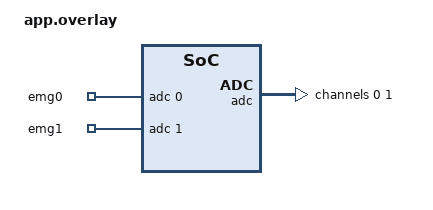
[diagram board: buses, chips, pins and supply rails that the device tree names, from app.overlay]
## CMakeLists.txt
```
cmake_minimum_required(VERSION 3.20.0)

find_package(Zephyr REQUIRED HINTS $ENV{ZEPHYR_BASE})

project(wearable)

target_sources(app PRIVATE
    src/main.c
    src/imu.c
    src/orientation.c
    src/emg.c
    src/emg_model.c
    src/emg_inference.c
    src/gesture_engine.c
    src/sensor_stream.c
    src/ble.c
    src/swipe.c
    ../common/myo_ble_client.c
)

target_include_directories(app PRIVATE
    ${CMAKE_CURRENT_SOURCE_DIR}/../common
)
```

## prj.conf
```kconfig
CONFIG_GPIO=y

# Zephyr logging
CONFIG_LOG=y
CONFIG_LOG_DEFAULT_LEVEL=3
CONFIG_LOG_MODE_DEFERRED=y

# IMU
CONFIG_SENSOR=y
CONFIG_I2C=y
CONFIG_REGULATOR=y
CONFIG_LSM6DSL=y

CONFIG_ADC=y

# BLE Central
CONFIG_BT=y
CONFIG_BT_CENTRAL=y
CONFIG_BT_GATT_CLIENT=y
CONFIG_BT_MAX_CONN=1

# USB CDC serial recording
CONFIG_USB_DEVICE_STACK_NEXT=y
CONFIG_CDC_ACM_SERIAL_INITIALIZE_AT_BOOT=y
CONFIG_SERIAL=y
CONFIG_CONSOLE=y
CONFIG_UART_CONSOLE=y
CONFIG_UART_LINE_CTRL=y
CONFIG_PRINTK=y

# Keep high-rate sample output out of deferred logging.
CONFIG_LOG_PRINTK=n
```

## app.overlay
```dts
#include <zephyr/dt-bindings/adc/nrf-saadc.h>

/ {
    zephyr,user {
        io-channels = <&adc 0>, <&adc 1>;
        io-channel-names = "emg0", "emg1";
    };
};

&adc {
    status = "okay";

    #address-cells = <1>;
    #size-cells = <0>;

    // MyoWare 0 - XIAO D0 (AIN0)
    channel@0 {
        reg = <0>;

        zephyr,gain = "ADC_GAIN_1_6";
        zephyr,reference = "ADC_REF_INTERNAL";
        zephyr,acquisition-time = <ADC_ACQ_TIME_DEFAULT>;

        zephyr,input-positive = <NRF_SAADC_AIN0>;

        zephyr,resolution = <12>;
    };

    // MyoWare 1 - XIAO D1 (AIN1)
    channel@1 {
        reg = <1>;

        zephyr,gain = "ADC_GAIN_1_6";
        zephyr,reference = "ADC_REF_INTERNAL";
        zephyr,acquisition-time = <ADC_ACQ_TIME_DEFAULT>;

        zephyr,input-positive = <NRF_SAADC_AIN1>;

        zephyr,resolution = <12>;
    };
};
```

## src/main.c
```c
#include <errno.h>
#include <math.h>
#include <zephyr/kernel.h>
#include <zephyr/device.h>
#include <zephyr/drivers/gpio.h>
#include <zephyr/logging/log.h>
#include "emg.h"
#include "imu.h"
#include "orientation.h"
#include "ble.h"
#include "myo_ble.h"
#include "sensor_stream.h"
#include "emg_inference.h"
#include "gesture_engine.h"
#include "myo_ble_client.h"

LOG_MODULE_REGISTER(wearable, LOG_LEVEL_INF);

#define LED0_NODE DT_ALIAS(led0)
#define CALIBRATION_SAMPLES 100
#define CALIBRATION_INTERVAL_MS 20
#define CALIBRATION_MAX_DRIFT_COS 0.9781476f
#define SENSOR_WARNING_INTERVAL_MS 1000
#define SAMPLE_INTERVAL_MS 50
#define BLE_HEARTBEAT_MS 500
#define GC_TX_DEPTH 8U
#define GC_TX_MAX_AGE_MS 450U

static const struct gpio_dt_spec led =
    GPIO_DT_SPEC_GET(LED0_NODE, gpios);

// Orientation gate owned by acquisition thread.
static struct gesture_engine gesture_control;

// Short-lived main-thread FIFO: no events survive receiver changes.
struct pending_gesture {
    enum myo_gesture gesture;
    uint32_t created_ms;
    uint32_t link_generation;
};

static struct pending_gesture tx_queue[GC_TX_DEPTH];
static uint8_t tx_head, tx_tail, tx_count;
static uint32_t tx_submitted, tx_dropped;

static void gesture_tx_clear(void)
{
    tx_head = tx_tail = tx_count = 0;
}

static void gesture_tx_pop(void)
{
    if (tx_count == 0U) return;
    tx_head = (uint8_t)((tx_head + 1U) % GC_TX_DEPTH);
    tx_count--;
}

static void gesture_tx_enqueue(enum myo_gesture gesture,
                               uint32_t now_ms)
{
    if (!myo_ble_client_gesture_ready()) {
        tx_dropped++;
        LOG_WRN("Gesture %d dropped: receiver unavailable", (int)gesture);
        return;
    }
    if (tx_count >= GC_TX_DEPTH) {
        tx_dropped++;
        LOG_WRN("Gesture %d dropped: TX queue full", (int)gesture);
        return;
    }

    struct pending_gesture *item = &tx_queue[tx_tail];
    item->gesture = gesture;
    item->created_ms = now_ms;
    item->link_generation = myo_ble_client_link_generation();
    tx_tail = (uint8_t)((tx_tail + 1U) % GC_TX_DEPTH);
    tx_count++;
}

static void gesture_tx_poll(uint32_t now_ms)
{
    while (tx_count > 0U) {
        struct pending_gesture *item = &tx_queue[tx_head];
        if ((uint32_t)(now_ms - item->created_ms) >
                GC_TX_MAX_AGE_MS ||
            item->link_generation != myo_ble_client_link_generation() ||
            !myo_ble_client_gesture_ready()) {
            tx_dropped++;
            gesture_tx_pop();
            continue;
        }

        int err = myo_ble_client_send_gesture(item->gesture);
        if (err == -EAGAIN || err == -ENOMEM) break;

        if (err == 0) {
            tx_submitted++;
            LOG_INF("Gesture BLE submitted: %d", (int)item->gesture);
        } else {
            tx_dropped++;
            LOG_WRN("Gesture BLE submission failed: %d", err);
        }
        gesture_tx_pop();
    }
}


#define EMG_BASELINE_SAMPLES 40
#define EMG_BASELINE_INTERVAL_MS 50
#define EMG_BASELINE_TIMEOUT_MS 5000

static void blink_work_handler(struct k_work *work);

K_WORK_DELAYABLE_DEFINE(blink_work, blink_work_handler);

static void blink_work_handler(struct k_work *work)
{
    ARG_UNUSED(work);

    uint32_t phase = k_uptime_get_32() % 1200U;
    bool ready = myo_ble_client_gesture_ready();

    bool on;
    if (!ready) {
        on = phase < 120U; // Single pulse: disconnected
    } else if (myo_ble_client_get_mode() == MYO_MODE_LIGHT) {
        on = true;         // Solid: Wio ready
    } else {
        on = phase < 120U ||
             (phase >= 280U && phase < 400U); // Laptop ready
    }

    gpio_pin_set_dt(&led, on ? 1 : 0);
    k_work_reschedule(&blink_work, K_MSEC(100));
}


static int capture_emg_baseline(int32_t baseline_mv[2])
{
    if (baseline_mv == NULL) return -EINVAL;

    int64_t sum[2] = {0, 0};
    uint32_t count = 0;
    uint32_t last_sequence = UINT32_MAX;
    int64_t deadline = k_uptime_get() + EMG_BASELINE_TIMEOUT_MS;

    while (count < EMG_BASELINE_SAMPLES &&
           k_uptime_get() < deadline) {
        struct sensor_frame frame;

        if (sensor_stream_latest(&frame) == 0 &&
            frame.sequence != last_sequence) {
            last_sequence = frame.sequence;
            int32_t emg0 = frame.emg.mv[0];
            int32_t emg1 = frame.emg.mv[1];

            if (emg0 < 0 || emg0 > 3300 ||
                emg1 < 0 || emg1 > 3300) {
                return -EINVAL;
            }
            sum[0] += emg0;
            sum[1] += emg1;
            count++;
        }

        k_msleep(EMG_BASELINE_INTERVAL_MS);
    }

    if (count != EMG_BASELINE_SAMPLES) return -EAGAIN;

    baseline_mv[0] = (int32_t)(sum[0] / EMG_BASELINE_SAMPLES);
    baseline_mv[1] = (int32_t)(sum[1] / EMG_BASELINE_SAMPLES);
    return 0;
}

static int capture_startup_reference(
    struct imu_accel_sample *reference)
{
    if (reference == NULL) return -EINVAL;

    int64_t sum_x = 0, sum_y = 0, sum_z = 0;
    struct imu_accel_sample first = {0};
    float first_magnitude = 0.0f;

    for (int i = 0; i < CALIBRATION_SAMPLES; i++) {
        struct imu_accel_sample sample;
        int err = imu_read_accel(&sample);
        if (err < 0) return err;

        float x = (float)sample.x_mg;
        float y = (float)sample.y_mg;
        float z = (float)sample.z_mg;
        float magnitude = sqrtf(x*x + y*y + z*z);

        if (magnitude < 800.0f || magnitude > 1200.0f) {
            return -EAGAIN;
        }

        if (i == 0) {
            first = sample;
            first_magnitude = magnitude;
        } else {
            float dot =
                x * first.x_mg +
                y * first.y_mg +
                z * first.z_mg;

            // Reject calibration if the arm drifts by over 12 degrees.
            if (dot < CALIBRATION_MAX_DRIFT_COS *
                      magnitude * first_magnitude) {
                return -EAGAIN;
            }
        }

        sum_x += sample.x_mg;
        sum_y += sample.y_mg;
        sum_z += sample.z_mg;
        k_msleep(CALIBRATION_INTERVAL_MS);
    }

    reference->x_mg = (int32_t)(sum_x / CALIBRATION_SAMPLES);
    reference->y_mg = (int32_t)(sum_y / CALIBRATION_SAMPLES);
    reference->z_mg = (int32_t)(sum_z / CALIBRATION_SAMPLES);
    return 0;
}

int main(void)
{
    if (!gpio_is_ready_dt(&led)) {
        return 0;
    }

    gpio_pin_configure_dt(&led, GPIO_OUTPUT_INACTIVE);

    LOG_INF("Hand Controlled Smart Light starting");

    k_work_schedule(&blink_work, K_NO_WAIT);

    k_msleep(3000);

    int imu_status = imu_init();

    LOG_INF("imu_init() returned %d", imu_status);

    if (imu_status < 0) {
        LOG_ERR("IMU initialization failed");
        return 0;
    }

    if (emg_init() < 0) {
        LOG_ERR("EMG ADC initialization failed");
        return 0;
    }

    // Capture one shared orientation reference at startup.
    struct imu_accel_sample reference = {0};

    while (1) {
        LOG_INF("STARTUP ORIENTATION CALIBRATION");
        LOG_INF("Hold wearable in your control position.");
        LOG_INF("Hold still during the 2-second capture.");
        LOG_INF("Starting calibration in 2 seconds...");
        k_msleep(2000);

        int err = capture_startup_reference(&reference);
        if (err == 0) {
            LOG_INF("Orientation calibration successful.");
            break;
        }
        LOG_WRN("Calibration failed (%d); retrying...", err);
        k_msleep(500);
    }

    LOG_INF("Gate reference: X=%d Y=%d Z=%d",
            reference.x_mg, reference.y_mg, reference.z_mg);
    LOG_INF("Reference applies to both Light and Laptop modes.");

    // Start BLE after sensor calibration
    if (ble_init() < 0) {
        LOG_ERR("BLE initialization failed");
        return 0;
    }
    // Start continuous EMG + IMU acquisition.
    int stream_err = sensor_stream_start(&reference);
    if (stream_err < 0) {
        LOG_ERR("Sensor stream failed: %d", stream_err);
        return 0;
    }
        
    // Rest-only calibration supports four discrete EMG classes.
    int32_t rest_mv[2] = {0, 0};
    bool emg_calibrated = false;

    for (int attempt = 1; attempt <= 3; attempt++) {
        LOG_INF("EMG REST CALIBRATION");
        LOG_INF("Relax your forearm completely.");
        LOG_INF("Starting in 2 seconds.");
        k_msleep(2000);

        int err = capture_emg_baseline(rest_mv);
        if (err == 0) {
            emg_calibrated = emg_inference_set_baseline(
                rest_mv[0], rest_mv[1]);
            if (emg_calibrated) {
                LOG_INF("EMG calibrated: EMG0=%d mV, EMG1=%d mV",
                        rest_mv[0], rest_mv[1]);
                break;
            }
            err = -EINVAL;
        }
        LOG_WRN("EMG calibration attempt %d failed: %d", attempt, err);
    }

    if (!emg_calibrated) {
        LOG_ERR("EMG calibration failed; reboot to retry.");
        LOG_ERR("IMU acquisition and BLE remain active.");
    }

    sensor_stream_clear_swipes();

    // Start command recognition in the disarmed state.
    gesture_engine_init(&gesture_control);

    uint32_t last_gesture_sequence = UINT32_MAX;


    uint8_t last_sent = 0xff;
    int64_t last_tx_ms = 0;
    int64_t last_log_ms = 0;
    int64_t last_sensor_warning_ms = 0;
    int last_reported_class = -2;
    uint32_t last_swipe_diag_ms = k_uptime_get_32();

    while (1) {
        struct sensor_frame frame = {0};

        int ret = sensor_stream_latest(&frame);        

        bool valid = false;

        if (ret == 0) {

            valid = frame.orientation_valid;

            // Read the latest EMG ML prediction.
            emg_class_t predicted_class = EMG_REST;

            bool prediction_ready =
                emg_inference_latest(&predicted_class);

            int angle = frame.orientation_angle_deg;

            // Run command recognition only for fresh sensor data.
            uint32_t gesture_now = k_uptime_get_32();

            bool fresh_gesture_frame =
                frame.sequence != last_gesture_sequence &&
                (uint32_t)(gesture_now - frame.timestamp_ms) <= 150U;

            if (fresh_gesture_frame) {

                last_gesture_sequence = frame.sequence;

                // Read all pending IMU swipe events.
                // Ignore events older than 350 ms.
                struct swipe_notification notification;
                enum swipe_event pending_swipe = SWIPE_NONE;

                while (sensor_stream_pop_swipe(&notification)) {
                    if ((uint32_t)(
                            gesture_now - notification.timestamp_ms
                        ) <= 350U) {

                        pending_swipe = notification.event;
                    }
                }

                // Suppress FLEX candidates during substantial
                // wrist movement. Raw gyro units are mdps.
                // 35000 mdps = 35 degrees/second.
                const int32_t motion_threshold = 35000;

                bool significant_motion =
                    frame.motion.gyro.x_mdps > motion_threshold ||
                    frame.motion.gyro.x_mdps < -motion_threshold ||
                    frame.motion.gyro.y_mdps > motion_threshold ||
                    frame.motion.gyro.y_mdps < -motion_threshold ||
                    frame.motion.gyro.z_mdps > motion_threshold ||
                    frame.motion.gyro.z_mdps < -motion_threshold;

                // Interpret all seven discrete gestures. Swipes are active
                // in either receiver mode; the sensor thread gated onset.
                enum myo_gesture action = gesture_engine_update(
                    &gesture_control,
                    gesture_now,
                    valid,
                    prediction_ready,
                    prediction_ready ? predicted_class : EMG_UNKNOWN,
                    significant_motion,
                    pending_swipe
                );

                if (pending_swipe != SWIPE_NONE &&
                    action == MYO_GESTURE_NONE) {
                    LOG_INF("Swipe %d suppressed by gesture engine",
                            (int)pending_swipe);
                }

                // A five-second TENSE changes receivers in any pose.
                // A shorter released TENSE remains a normal event.
                if (gesture_engine_take_mode_switch(
                        &gesture_control)) {
                    LOG_INF("Long TENSE: changing receiver mode");
                    sensor_stream_clear_swipes();

                    gesture_tx_clear();
                    int mode_err = myo_ble_client_toggle_mode();
                    if (mode_err) {
                        LOG_WRN("Mode switch error: %d", mode_err);
                    } else {
                        LOG_INF("Receiver mode: %s",
                            myo_ble_client_get_mode() == MYO_MODE_LIGHT
                                ? "LIGHT" : "LAPTOP");
                    }
                }

                if (action != MYO_GESTURE_NONE) {
                    gesture_tx_enqueue(action, gesture_now);
                }
            }

            const char *gesture = "WARMUP";
            int class_code = -1;

            if (prediction_ready) {
                class_code = (int)predicted_class;

                switch (predicted_class) {
                case EMG_REST:
                    gesture = "REST";
                    break;

                case EMG_FLEX:
                    gesture = "FLEX";
                    break;

                case EMG_EXTEND:
                    gesture = "EXTEND";
                    break;

                case EMG_TENSE:
                    gesture = "TENSE";
                    break;

                default:
                    gesture = "UNKNOWN";
                    break;
                }
            }

            int64_t log_now = k_uptime_get();

            // Log periodically and when the classification changes.
            // Throttle changes to avoid flooding the console.
            if ((log_now - last_log_ms >= 250) ||
                (class_code != last_reported_class &&
                log_now - last_log_ms >= 100)) {

                LOG_INF(
                    "EMG0=%d mV | EMG1=%d mV | Gesture=%s | "
                    "Orientation=%s | Angle=%d",
                    frame.emg.mv[0], frame.emg.mv[1], gesture,
                    valid ? "VALID" : "INVALID", angle
                );

                last_reported_class = class_code;
                last_log_ms = log_now;
            }
        } else {
            // Never complete a hold based on missing/stale samples.
            gesture_engine_abort(&gesture_control);
            gesture_tx_clear();
            sensor_stream_clear_swipes();

            int64_t warning_now = k_uptime_get();
            if (warning_now - last_sensor_warning_ms >=
                SENSOR_WARNING_INTERVAL_MS) {
                LOG_WRN("Sensor frame unavailable or stale: %d", ret);
                last_sensor_warning_ms = warning_now;
            }

        }
        
        // Validity heartbeat now means fresh sensor data. The
        // orientation gate remains available for diagnostics only.
        uint8_t state = ret == 0 ? MYO_VALID : MYO_INVALID;

        int64_t now = k_uptime_get();

        if (state != last_sent ||
            now - last_tx_ms >= BLE_HEARTBEAT_MS) {

            if (ble_send_state(state) == 0) {
                last_sent = state;
                last_tx_ms = now;
            }
        }
                
        // Report pipeline failures without printing every IMU sample.
        uint32_t diag_now = k_uptime_get_32();
        if ((uint32_t)(diag_now - last_swipe_diag_ms) >= 3000U) {
            struct swipe_stats stats = {0};
            uint32_t queue_drops = 0;
            sensor_stream_get_swipe_stats(&stats, &queue_drops);

            LOG_INF("SWIPE attempts=%u accepted=%u grace=%u "
                    "gate_blocked=%u below_threshold=%u",
                    stats.attempts, stats.accepted, stats.grace_starts,
                    stats.gate_blocked, stats.below_threshold);

            LOG_INF("SWIPE weak=%u direction=%u ambiguous=%u "
                    "rearms=%u gaps=%u queue_drops=%u",
                    stats.weak_capture, stats.direction_rejected,
                    stats.ambiguous_rejected, stats.rearms, stats.gaps,
                    queue_drops);

            uint32_t acked = 0, rejected = 0;
            myo_ble_client_get_gesture_stats(&acked, &rejected);
            LOG_INF("BLE submitted=%u acked=%u rejected=%u "
                    "dropped=%u pending=%u",
                    tx_submitted, acked, rejected, tx_dropped,
                    (unsigned int)tx_count);

            last_swipe_diag_ms = diag_now;
        }

        // Discrete actions only, never continuous EMG brightness.
        gesture_tx_poll(k_uptime_get_32());
        k_msleep(SAMPLE_INTERVAL_MS);
    }

    return 0;
}
```

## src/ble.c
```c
#include "ble.h"
#include "myo_ble_client.h"

int ble_init(void)
{
    return myo_ble_client_init();
}

int ble_send_state(uint8_t state)
{
    return myo_ble_client_send_state(state);
}
```

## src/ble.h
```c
#ifndef BLE_H
#define BLE_H

#include <stdint.h>

int ble_init(void);
int ble_send_state(uint8_t state);

#endif
```

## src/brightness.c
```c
#include "brightness.h"

#define FILTER_MS 500.0f
#define CONFIRM_MS 250U
#define HYSTERESIS 0.075f

static float clamp(float value, float lo, float hi)
{
    if (value < lo) return lo;
    if (value > hi) return hi;
    return value;
}

void brightness_init(struct brightness_estimator *b,
                     float baseline_mv,
                     float maximum_mv)
{
    if (!b) return;

    if (maximum_mv <= baseline_mv + 1.0f) {
        maximum_mv = baseline_mv + 1.0f;
    }

    *b = (struct brightness_estimator){0};

    b->baseline_mv = baseline_mv;
    b->maximum_mv = maximum_mv;
        
    // Start at a usable 50% brightness.
    b->filtered_mv =
        baseline_mv + 0.5f * (maximum_mv - baseline_mv);

    b->level = 2;
    b->candidate = 2;
    b->initialized = true;
}

uint8_t brightness_get(const struct brightness_estimator *b)
{
    return b ? b->level * 25U : 0U;
}

uint8_t brightness_update(struct brightness_estimator *b,
                          int32_t emg0_mv,
                          uint32_t timestamp_ms,
                          bool orientation_valid)
{
    if (!b || !b->initialized) return 0;

    // Invalid orientation freezes brightness.
    if (!orientation_valid) {
        b->last_ms = timestamp_ms;
        b->candidate_since_ms = 0;
        b->candidate = b->level;
        return brightness_get(b);
    }

    uint32_t dt = timestamp_ms - b->last_ms;

    if (b->last_ms == 0 || dt > 1000U) {
        dt = 10U;
    }

    b->last_ms = timestamp_ms;

    // Time-based low-pass filter, compatible with
    // either 20 Hz testing or 100 Hz integration.
    float alpha = (float)dt / (FILTER_MS + (float)dt);

    b->filtered_mv += alpha *
        ((float)emg0_mv - b->filtered_mv);

    float intensity =
        (b->filtered_mv - b->baseline_mv) /
        (b->maximum_mv - b->baseline_mv);

    intensity = clamp(intensity, 0.0f, 1.0f);

    uint8_t proposed = b->level;

    // Adjacent-level thresholds with hysteresis.
    // Moving only one step at a time reduces jumps.
    if (b->level < 4) {
        float up_threshold =
            ((float)b->level + 0.5f) / 4.0f;

        if (intensity > up_threshold + HYSTERESIS) {
            proposed = b->level + 1;
        }
    }

    if (b->level > 0) {
        float down_threshold =
            ((float)b->level - 0.5f) / 4.0f;

        if (intensity < down_threshold - HYSTERESIS) {
            proposed = b->level - 1;
        }
    }

    if (proposed == b->level) {
        b->candidate = b->level;
        b->candidate_since_ms = 0;
        return brightness_get(b);
    }

    if (proposed != b->candidate ||
        b->candidate_since_ms == 0) {
        b->candidate = proposed;
        b->candidate_since_ms = timestamp_ms;
        return brightness_get(b);
    }

    if ((uint32_t)(timestamp_ms - b->candidate_since_ms)
        >= CONFIRM_MS) {
        b->level = proposed;
        b->candidate_since_ms = 0;
    }

    return brightness_get(b);
}
```

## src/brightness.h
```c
#ifndef BRIGHTNESS_H
#define BRIGHTNESS_H

#include <stdbool.h>
#include <stdint.h>

struct brightness_estimator {
    float baseline_mv;
    float maximum_mv;
    float filtered_mv;
    uint32_t last_ms;
    uint32_t candidate_since_ms;
    uint8_t level;
    uint8_t candidate;
    bool initialized;
};

void brightness_init(struct brightness_estimator *b,
                     float baseline_mv,
                     float maximum_mv);

uint8_t brightness_update(struct brightness_estimator *b,
                          int32_t emg0_mv,
                          uint32_t timestamp_ms,
                          bool orientation_valid);

uint8_t brightness_get(const struct brightness_estimator *b);

#endif
```

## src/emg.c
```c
#include "emg.h"

#include <errno.h>

#include <zephyr/device.h>
#include <zephyr/devicetree.h>
#include <zephyr/drivers/adc.h>
#include <zephyr/logging/log.h>
#include <zephyr/sys/util.h>

LOG_MODULE_REGISTER(emg, LOG_LEVEL_INF);

#define EMG_NODE DT_PATH(zephyr_user)

static const struct adc_dt_spec emg_adc[EMG_CHANNEL_COUNT] = {
    ADC_DT_SPEC_GET_BY_NAME(EMG_NODE, emg0),
    ADC_DT_SPEC_GET_BY_NAME(EMG_NODE, emg1),
};

int emg_init(void)
{
    // Both channels must use the same ADC peripheral.
    if (emg_adc[0].dev != emg_adc[1].dev) {
        LOG_ERR("EMG channels use different ADC devices");
        return -EINVAL;
    }

    for (int i = 0; i < EMG_CHANNEL_COUNT; i++) {

        if (!adc_is_ready_dt(&emg_adc[i])) {
            LOG_ERR("EMG%d ADC device not ready", i);
            return -ENODEV;
        }

        int ret = adc_channel_setup_dt(&emg_adc[i]);

        if (ret < 0) {
            LOG_ERR("EMG%d ADC setup failed: %d", i, ret);
            return ret;
        }
    }

    LOG_INF("Both EMG ADC channels initialized");

    return 0;
}

int emg_read(struct emg_sample *sample)
{
    if (sample == NULL) {
        return -EINVAL;
    }

    int16_t raw[EMG_CHANNEL_COUNT] = {0};

    // Read both ADC channels in one sampling sequence.
    struct adc_sequence sequence = {
        .channels = BIT(emg_adc[0].channel_id) |
                    BIT(emg_adc[1].channel_id),
        .buffer = raw,
        .buffer_size = sizeof(raw),
        .resolution = emg_adc[0].resolution,
    };

    int ret = adc_read(emg_adc[0].dev, &sequence);

    if (ret < 0) {
        return ret;
    }

    // Convert both ADC readings to millivolts.
    for (int i = 0; i < EMG_CHANNEL_COUNT; i++) {

        sample->raw[i] = raw[i];

        int32_t mv = raw[i];

        ret = adc_raw_to_millivolts_dt(
            &emg_adc[i],
            &mv);

        if (ret < 0) {
            return ret;
        }

        sample->mv[i] = mv;
    }

    return 0;
}
```

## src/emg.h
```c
#ifndef EMG_H
#define EMG_H

#include <stdint.h>

#define EMG_CHANNEL_COUNT 2

struct emg_sample {
    int16_t raw[EMG_CHANNEL_COUNT];
    int32_t mv[EMG_CHANNEL_COUNT];
};

int emg_init(void);
int emg_read(struct emg_sample *sample);

#endif
```

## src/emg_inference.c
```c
#include "emg_inference.h"

#include <stdbool.h>
#include <stdint.h>
#include <zephyr/kernel.h>
#include <zephyr/sys/atomic.h>

#define EMG_CHANNELS 2U
#define EMG_WINDOW 40U
#define EMG_HOP 10U
#define EMG_MAX_GAP_MS 25U
#define CONFIRM_WINDOWS 2U
#define UNKNOWN_TIMEOUT_WINDOWS 3U

#if EMG_FEATURE_COUNT != 8
#error "Dual-channel inference requires eight EMG features"
#endif

K_MUTEX_DEFINE(emg_inference_lock);

static int32_t samples[EMG_CHANNELS][EMG_WINDOW];
static float baseline_mv[EMG_CHANNELS];
static bool baseline_ready;

static uint32_t write_index;
static uint32_t samples_seen;
static uint32_t previous_sequence;
static uint32_t previous_timestamp;
static bool have_previous;

static emg_class_t stable_class = EMG_UNKNOWN;
static emg_class_t candidate_class = EMG_UNKNOWN;
static uint32_t candidate_windows;
static uint32_t unknown_windows;

// Atomically read by the main thread. 0=unavailable; 1..4=class+1.
static atomic_t latest_state;

static void reset_prediction_locked(void)
{
    write_index = 0;
    samples_seen = 0;
    have_previous = false;
    stable_class = EMG_UNKNOWN;
    candidate_class = EMG_UNKNOWN;
    candidate_windows = 0;
    unknown_windows = 0;
    atomic_set(&latest_state, 0);
}

bool emg_inference_set_baseline(int32_t emg0_mv, int32_t emg1_mv)
{
    if (emg0_mv < 0 || emg0_mv > 3300 ||
        emg1_mv < 0 || emg1_mv > 3300) {
        return false;
    }

    k_mutex_lock(&emg_inference_lock, K_FOREVER);
    baseline_mv[0] = (float)emg0_mv;
    baseline_mv[1] = (float)emg1_mv;
    reset_prediction_locked();
    baseline_ready = true;
    k_mutex_unlock(&emg_inference_lock);
    return true;
}

void emg_inference_invalidate(void)
{
    k_mutex_lock(&emg_inference_lock, K_FOREVER);
    reset_prediction_locked();
    k_mutex_unlock(&emg_inference_lock);
}

static void update_stable_class(emg_class_t predicted)
{
    if (predicted == EMG_UNKNOWN) {
        unknown_windows++;
        candidate_class = EMG_UNKNOWN;
        candidate_windows = 0;

        if (unknown_windows >= UNKNOWN_TIMEOUT_WINDOWS) {
            stable_class = EMG_UNKNOWN;
            atomic_set(&latest_state, 0);
        }
        return;
    }

    unknown_windows = 0;

    if (predicted == stable_class) {
        candidate_class = EMG_UNKNOWN;
        candidate_windows = 0;
        return;
    }

    if (predicted != candidate_class) {
        candidate_class = predicted;
        candidate_windows = 1;
        return;
    }

    candidate_windows++;
    if (candidate_windows >= CONFIRM_WINDOWS) {
        stable_class = predicted;
        candidate_class = EMG_UNKNOWN;
        candidate_windows = 0;
        atomic_set(&latest_state, (atomic_val_t)stable_class + 1);
    }
}

void emg_inference_push(
    int32_t emg0_mv,
    int32_t emg1_mv,
    uint32_t sequence,
    uint32_t timestamp_ms)
{
    k_mutex_lock(&emg_inference_lock, K_FOREVER);

    if (!baseline_ready) {
        k_mutex_unlock(&emg_inference_lock);
        return;
    }

    if (emg0_mv < 0 || emg0_mv > 3300 ||
        emg1_mv < 0 || emg1_mv > 3300) {
        reset_prediction_locked();
        k_mutex_unlock(&emg_inference_lock);
        return;
    }

    if (have_previous) {
        uint32_t dt = timestamp_ms - previous_timestamp;
        if (sequence != previous_sequence + 1U ||
            dt == 0U || dt > EMG_MAX_GAP_MS) {
            reset_prediction_locked();
        }
    }

    previous_sequence = sequence;
    previous_timestamp = timestamp_ms;
    have_previous = true;
    samples[0][write_index] = emg0_mv;
    samples[1][write_index] = emg1_mv;
    write_index = (write_index + 1U) % EMG_WINDOW;
    samples_seen++;

    // First complete window takes 400 ms. Predict each 100 ms.
    if (samples_seen < EMG_WINDOW ||
        (samples_seen - EMG_WINDOW) % EMG_HOP != 0U) {
        k_mutex_unlock(&emg_inference_lock);
        return;
    }

    float features[EMG_FEATURE_COUNT];

    for (uint32_t channel = 0; channel < EMG_CHANNELS; channel++) {
        int32_t minimum = samples[channel][0];
        int32_t maximum = samples[channel][0];
        int64_t sum = 0;

        for (uint32_t i = 0; i < EMG_WINDOW; i++) {
            int32_t value = samples[channel][i];
            sum += value;
            if (value < minimum) minimum = value;
            if (value > maximum) maximum = value;
        }

        float mean = (float)sum / (float)EMG_WINDOW;
        float variance_sum = 0.0f;

        for (uint32_t i = 0; i < EMG_WINDOW; i++) {
            float difference = (float)samples[channel][i] - mean;
            variance_sum += difference * difference;
        }

        uint32_t idx = channel * 4U;
        features[idx] = mean;
        features[idx + 1U] = (float)maximum;
        features[idx + 2U] = variance_sum / (float)EMG_WINDOW;
        features[idx + 3U] = (float)(maximum - minimum);
    }

    update_stable_class(emg_model_predict(features, baseline_mv));
    k_mutex_unlock(&emg_inference_lock);
}

bool emg_inference_latest(emg_class_t *result)
{
    if (result == NULL) return false;

    atomic_val_t state = atomic_get(&latest_state);
    if (state < 1 || state > 4) return false;

    *result = (emg_class_t)(state - 1);
    return true;
}
```

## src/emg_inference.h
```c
#ifndef EMG_INFERENCE_H
#define EMG_INFERENCE_H

#include <stdbool.h>
#include <stdint.h>
#include "emg_model.h"

// Recalibrates resting voltage on both sensors, resets inference.
bool emg_inference_set_baseline(int32_t emg0_mv, int32_t emg1_mv);

// Feed every 100 Hz acquisition sample.
void emg_inference_push(
    int32_t emg0_mv,
    int32_t emg1_mv,
    uint32_t sequence,
    uint32_t timestamp_ms);

// Called on a sensor read error; preserves the resting baseline.
void emg_inference_invalidate(void);

// False during warmup, gaps or ambiguous readings.
bool emg_inference_latest(emg_class_t *result);

#endif
```

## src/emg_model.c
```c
#include "emg_model.h"

// Depth-3 decision tree trained on the recorded four-class EMG dataset.
// 400 ms windows, 100 ms hop, raw mV; all 8 features remain available.
// Independent validation: 375/406 windows = 92.36% accuracy.
// Do not subtract baseline: this tree was fit on absolute input voltages.
emg_class_t emg_model_predict(
    const float features[EMG_FEATURE_COUNT],
    const float baseline_mv[2])
{
    if (features == 0) return EMG_UNKNOWN;
    (void)baseline_mv;

    if (features[4] <= 6.936249924e+01f) {
        if (features[0] <= 7.766249847e+01f) {
            return EMG_REST;
        } else {
            return EMG_EXTEND;
        }
    } else {
        if (features[4] <= 8.092874756e+02f) {
            if (features[5] <= 3.665000000e+02f) {
                return EMG_EXTEND;
            } else {
                return EMG_TENSE;
            }
        } else {
            if (features[1] <= 5.905000000e+02f) {
                return EMG_FLEX;
            } else {
                return EMG_FLEX;
            }
        }
    }
}
```

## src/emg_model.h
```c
#ifndef EMG_MODEL_H
#define EMG_MODEL_H

typedef enum {
    EMG_REST = 0,
    EMG_FLEX = 1,
    EMG_EXTEND = 2,
    EMG_TENSE = 3,
    EMG_UNKNOWN = 4
} emg_class_t;

// mean, max, variance and range for EMG0 and EMG1
#define EMG_FEATURE_COUNT 8

emg_class_t emg_model_predict(
    const float features[EMG_FEATURE_COUNT],
    const float baseline_mv[2]);

#endif
```

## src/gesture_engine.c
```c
#include "gesture_engine.h"

#include <stddef.h>
#include <string.h>

#define REST_CONFIRM_MS          350U
#define TENSE_SHORT_MIN_MS       350U
#define TENSE_MODE_HOLD_MS      5000U
#define TENSE_RELEASE_GRACE_MS   250U
#define TENSE_MISSING_ABORT_MS   600U
#define MOTION_SETTLE_MS         200U
#define ACTION_COOLDOWN_MS       350U

static bool before_deadline(uint32_t now, uint32_t deadline)
{
    return (int32_t)(now - deadline) < 0;
}

static enum myo_gesture swipe_to_gesture(enum swipe_event swipe)
{
    switch (swipe) {
    case SWIPE_UP:
        return MYO_GESTURE_SWIPE_UP;
    case SWIPE_DOWN:
        return MYO_GESTURE_SWIPE_DOWN;
    case SWIPE_LEFT:
        return MYO_GESTURE_SWIPE_LEFT;
    case SWIPE_RIGHT:
        return MYO_GESTURE_SWIPE_RIGHT;
    default:
        return MYO_GESTURE_NONE;
    }
}

void gesture_engine_init(struct gesture_engine *engine)
{
    if (engine == NULL) {
        return;
    }

    memset(engine, 0, sizeof(*engine));
    // An intentional 350 ms REST is required before an EMG event.
    engine->emg_armed = false;
}

void gesture_engine_abort(struct gesture_engine *engine)
{
    if (engine == NULL) {
        return;
    }

    // Never complete a partially observed hold after sensor loss.
    engine->emg_armed = false;
    engine->rest_tracking = false;
    engine->tense_tracking = false;
    engine->tense_started_in_gate = false;
    engine->tense_mode_allowed = false;
    engine->mode_switch_pending = false;
}

enum myo_gesture gesture_engine_update(
    struct gesture_engine *engine,
    uint32_t now_ms,
    bool orientation_valid,
    bool emg_ready,
    emg_class_t emg_class,
    bool significant_motion,
    enum swipe_event swipe)
{
    if (engine == NULL) {
        return MYO_GESTURE_NONE;
    }

    // Demo mode: orientation validity remains diagnostic only.
    // Short TENSE is an action; continuous 5 s TENSE changes modes.
    (void)orientation_valid;

    // Motion temporarily prevents NEW EMG holds, not IMU swipes.
    if (significant_motion) {
        engine->motion_block_until_ms = now_ms + MOTION_SETTLE_MS;
    }

    // The swipe detector applies motion onset, direction and cooldown.
    // It intentionally does not require an orientation gate for the demo.
    enum myo_gesture swipe_action = swipe_to_gesture(swipe);

    if (swipe_action != MYO_GESTURE_NONE &&
        !engine->tense_tracking &&
        !before_deadline(now_ms, engine->cooldown_until_ms)) {
        engine->emg_armed = false;
        engine->rest_tracking = false;
        engine->cooldown_until_ms = now_ms + ACTION_COOLDOWN_MS;
        return swipe_action;
    }

    // Unknown / unavailable predictions are not interpreted as
    // releases. Allow short inference flicker during a TENSE.
    if (!emg_ready || emg_class == EMG_UNKNOWN) {
        if (engine->tense_tracking &&
            (uint32_t)(now_ms - engine->tense_last_seen_ms)
                < TENSE_MISSING_ABORT_MS) {
            return MYO_GESTURE_NONE;
        }

        gesture_engine_abort(engine);
        return MYO_GESTURE_NONE;
    }

    // A TENSE is latched to its starting orientation and
    // cannot switch between action and mode-change semantics.
    if (engine->tense_tracking) {
        if (emg_class == EMG_TENSE) {
            engine->tense_last_seen_ms = now_ms;

            // A long continuous TENSE changes modes in either pose.
            if (engine->tense_mode_allowed &&
                (uint32_t)(now_ms - engine->tense_since_ms)
                    >= TENSE_MODE_HOLD_MS) {
                engine->mode_switch_pending = true;
                engine->tense_tracking = false;
                engine->cooldown_until_ms = now_ms + ACTION_COOLDOWN_MS;
            }
            return MYO_GESTURE_NONE;
        }

        if ((uint32_t)(now_ms - engine->tense_last_seen_ms)
            < TENSE_RELEASE_GRACE_MS) {
            return MYO_GESTURE_NONE;
        }

        uint32_t held_ms = engine->tense_last_seen_ms -
                           engine->tense_since_ms;

        // Short TENSE: release to REST after at least 350 ms.
        // After 5 s, a continuous TENSE switches receiver modes.
        bool short_tense =
            engine->tense_started_in_gate &&
            emg_class == EMG_REST &&
            held_ms >= TENSE_SHORT_MIN_MS &&
            !before_deadline(now_ms, engine->cooldown_until_ms);

        engine->tense_tracking = false;
        engine->tense_mode_allowed = false;
        engine->tense_started_in_gate = false;

        if (short_tense) {
            engine->cooldown_until_ms = now_ms + ACTION_COOLDOWN_MS;
            return MYO_GESTURE_TENSE;
        }

        // Interrupted TENSE cannot immediately produce FLEX/EXTEND.
        return MYO_GESTURE_NONE;
    }

    // Stable REST is the single EMG rearm action in both modes.
    if (emg_class == EMG_REST) {
        if (!engine->rest_tracking) {
            engine->rest_tracking = true;
            engine->rest_since_ms = now_ms;
        } else if ((uint32_t)(now_ms - engine->rest_since_ms)
                   >= REST_CONFIRM_MS) {
            engine->emg_armed = true;
        }
        return MYO_GESTURE_NONE;
    }

    engine->rest_tracking = false;

    if (!engine->emg_armed ||
        before_deadline(now_ms, engine->cooldown_until_ms) ||
        before_deadline(now_ms, engine->motion_block_until_ms)) {
        return MYO_GESTURE_NONE;
    }

    if (emg_class == EMG_TENSE) {
        engine->emg_armed = false;
        engine->tense_tracking = true;
        engine->tense_since_ms = now_ms;
        engine->tense_last_seen_ms = now_ms;

        // Both durations are available in any orientation.
        // Release after 350 ms = TENSE; continuous 5 s = mode change.
        engine->tense_started_in_gate = true;
        engine->tense_mode_allowed = true;
        return MYO_GESTURE_NONE;
    }

    if (emg_class == EMG_FLEX ||
        emg_class == EMG_EXTEND) {
        // All normal EMG gestures work regardless of orientation.
        engine->emg_armed = false;

        engine->cooldown_until_ms = now_ms + ACTION_COOLDOWN_MS;

        return emg_class == EMG_FLEX
            ? MYO_GESTURE_FLEX
            : MYO_GESTURE_EXTEND;
    }

    return MYO_GESTURE_NONE;
}

bool gesture_engine_take_mode_switch(struct gesture_engine *engine)
{
    if (engine == NULL || !engine->mode_switch_pending) {
        return false;
    }

    engine->mode_switch_pending = false;
    return true;
}
```

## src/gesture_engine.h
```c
#ifndef GESTURE_ENGINE_H
#define GESTURE_ENGINE_H

#include <stdbool.h>
#include <stdint.h>

#include "emg_model.h"
#include "swipe.h"
#include "myo_ble.h"

// Gesture interpretation runs on the wearable main thread.
// Swipe detection and EMG inference run in sensor_stream.c.
struct gesture_engine {
    bool emg_armed;
    bool rest_tracking;
    bool tense_tracking;
    bool tense_started_in_gate;
    bool tense_mode_allowed;
    bool mode_switch_pending;

    uint32_t rest_since_ms;
    uint32_t tense_since_ms;
    uint32_t tense_last_seen_ms;
    uint32_t motion_block_until_ms;
    uint32_t cooldown_until_ms;
};

void gesture_engine_init(struct gesture_engine *engine);

// Abort unfinished EMG holds if sensor data is missing/stale.
void gesture_engine_abort(struct gesture_engine *engine);

enum myo_gesture gesture_engine_update(
    struct gesture_engine *engine,
    uint32_t now_ms,
    bool orientation_valid,
    bool emg_ready,
    emg_class_t emg_class,
    bool significant_motion,
    enum swipe_event swipe
);

// A five-second TENSE outside the orientation gate requests
// a local receiver change; no TENSE action is sent over BLE.
bool gesture_engine_take_mode_switch(
    struct gesture_engine *engine);

#endif
```
